# jbr_MDR1986VE3 register map
Registers are 32-bit, access not given, no defined reset value unless marked. A register's access mark holds for its fields unless they carry their own. Addresses are absolute; registers are grouped by the start of their names; [hi:lo] are bit positions; {n}, {i} and the like mark numbered series; 'fields as' and 'values as' point back to an identical list.

## SSP3
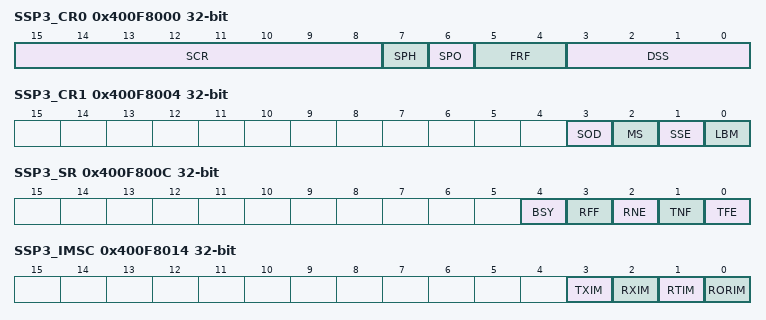
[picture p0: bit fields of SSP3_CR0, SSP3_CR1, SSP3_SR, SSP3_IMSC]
0x400F8000 SSP3_CR0
  [15:8] SCR, [7] SPH, [6] SPO, [5:4] FRF, [3:0] DSS
0x400F8004 SSP3_CR1
  [3] SOD, [2] MS, [1] SSE, [0] LBM
0x400F8008 SSP3_DR
  [15:0] DATA
0x400F800C SSP3_SR
  [4] BSY, [3] RFF, [2] RNE, [1] TNF, [0] TFE
0x400F8010 SSP3_CPSR
  [7:0] CPSDVSR
0x400F8014 SSP3_IMSC
  [3] TXIM, [2] RXIM, [1] RTIM, [0] RORIM
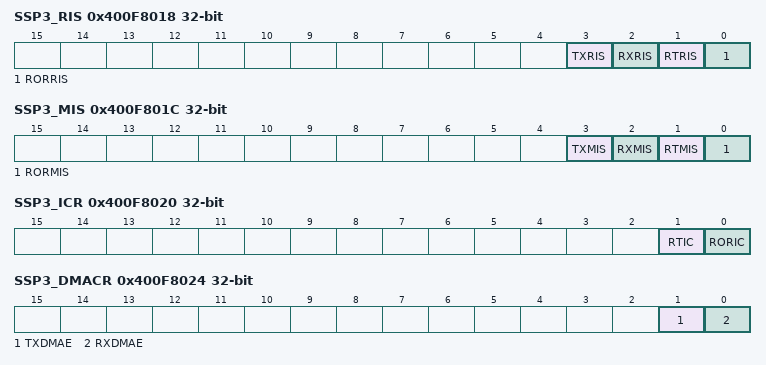
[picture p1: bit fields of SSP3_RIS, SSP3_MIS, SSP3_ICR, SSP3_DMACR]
0x400F8018 SSP3_RIS
  [3] TXRIS, [2] RXRIS, [1] RTRIS, [0] RORRIS
0x400F801C SSP3_MIS
  [3] TXMIS, [2] RXMIS, [1] RTMIS, [0] RORMIS
0x400F8020 SSP3_ICR
  [1] RTIC, [0] RORIC
0x400F8024 SSP3_DMACR
  [1] TXDMAE, [0] RXDMAE

## SSP4
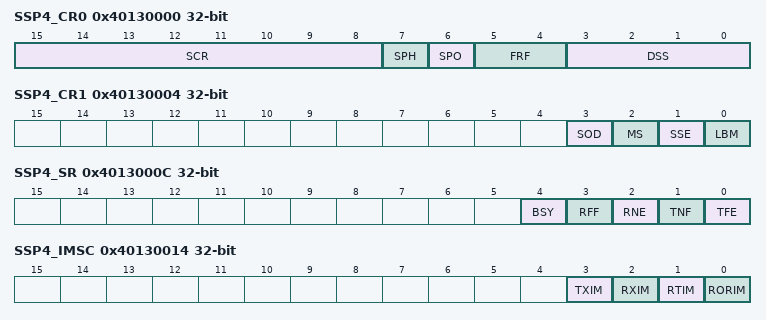
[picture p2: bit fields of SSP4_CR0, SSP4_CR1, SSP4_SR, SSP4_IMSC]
0x40130000 SSP4_CR0
  [15:8] SCR, [7] SPH, [6] SPO, [5:4] FRF, [3:0] DSS
0x40130004 SSP4_CR1
  [3] SOD, [2] MS, [1] SSE, [0] LBM
0x40130008 SSP4_DR
  [15:0] DATA
0x4013000C SSP4_SR
  [4] BSY, [3] RFF, [2] RNE, [1] TNF, [0] TFE
0x40130010 SSP4_CPSR
  [7:0] CPSDVSR
0x40130014 SSP4_IMSC
  [3] TXIM, [2] RXIM, [1] RTIM, [0] RORIM
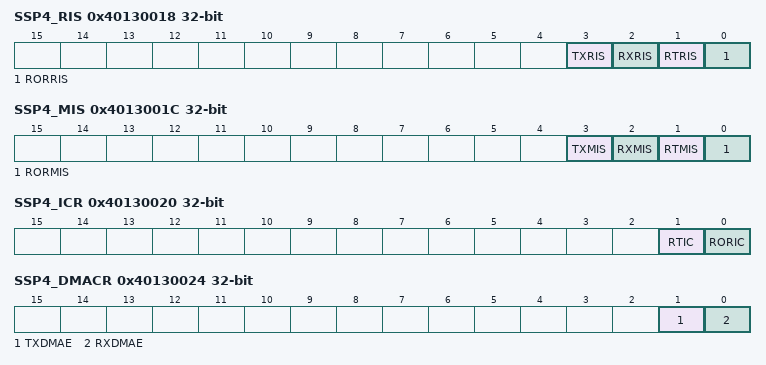
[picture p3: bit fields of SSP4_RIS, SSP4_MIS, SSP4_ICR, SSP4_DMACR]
0x40130018 SSP4_RIS
  [3] TXRIS, [2] RXRIS, [1] RTRIS, [0] RORRIS
0x4013001C SSP4_MIS
  [3] TXMIS, [2] RXMIS, [1] RTMIS, [0] RORMIS
0x40130020 SSP4_ICR
  [1] RTIC, [0] RORIC
0x40130024 SSP4_DMACR
  [1] TXDMAE, [0] RXDMAE

## MIL
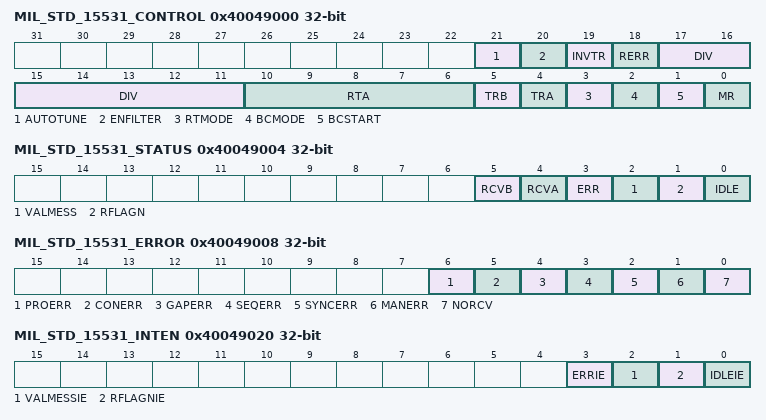
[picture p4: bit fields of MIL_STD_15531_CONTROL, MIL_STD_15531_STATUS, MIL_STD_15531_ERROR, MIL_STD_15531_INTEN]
0x40049000 MIL_STD_15531_CONTROL
  [21] AUTOTUNE, [20] ENFILTER, [19] INVTR, [18] RERR, [17:11] DIV, [10:6] RTA, [5] TRB, [4] TRA, [3] RTMODE, [2] BCMODE, [1] BCSTART, [0] MR
0x40049004 MIL_STD_15531_STATUS
  [5] RCVB, [4] RCVA, [3] ERR, [2] VALMESS, [1] RFLAGN, [0] IDLE
0x40049008 MIL_STD_15531_ERROR
  [6] PROERR, [5] CONERR, [4] GAPERR, [3] SEQERR, [2] SYNCERR, [1] MANERR, [0] NORCV
0x4004900C MIL_STD_15531_CommandWord1
0x40049010 MIL_STD_15531_CommandWord2
0x40049014 MIL_STD_15531_ModeData
0x40049018 MIL_STD_15531_StatusWord1
0x4004901C MIL_STD_15531_StatusWord2
0x40049020 MIL_STD_15531_INTEN
  [3] ERRIE, [2] VALMESSIE, [1] RFLAGNIE, [0] IDLEIE
0x40049024 MIL_STD_15531_MSG
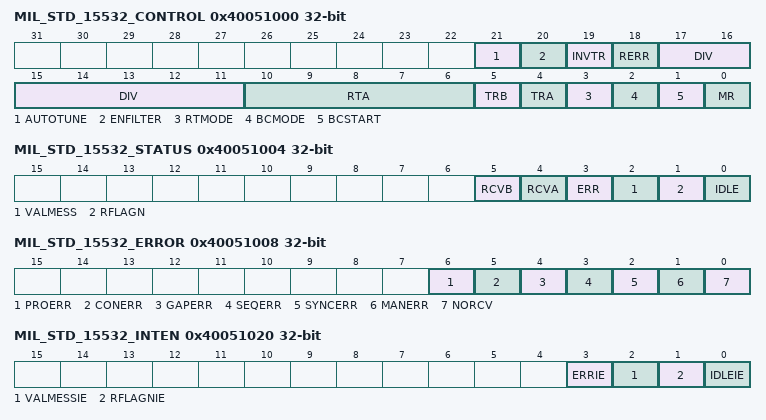
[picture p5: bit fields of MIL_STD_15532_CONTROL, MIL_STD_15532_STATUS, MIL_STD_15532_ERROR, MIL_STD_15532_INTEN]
0x40051000 MIL_STD_15532_CONTROL
  fields as MIL_STD_15531_CONTROL
0x40051004 MIL_STD_15532_STATUS
  [5] RCVB, [4] RCVA, [3] ERR, [2] VALMESS, [1] RFLAGN, [0] IDLE
0x40051008 MIL_STD_15532_ERROR
  fields as MIL_STD_15531_ERROR
0x4005100C MIL_STD_15532_CommandWord1
0x40051010 MIL_STD_15532_CommandWord2
0x40051014 MIL_STD_15532_ModeData
0x40051018 MIL_STD_15532_StatusWord1
0x4005101C MIL_STD_15532_StatusWord2
0x40051020 MIL_STD_15532_INTEN
  [3] ERRIE, [2] VALMESSIE, [1] RFLAGNIE, [0] IDLEIE
0x40051024 MIL_STD_15532_MSG

## ARINC429T
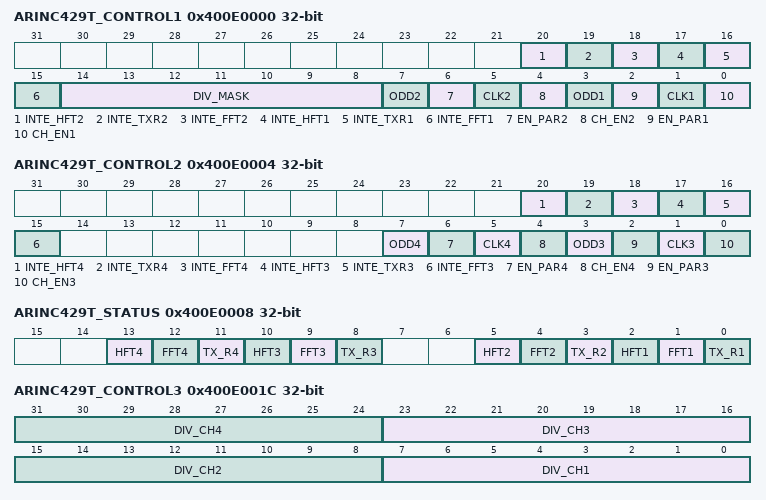
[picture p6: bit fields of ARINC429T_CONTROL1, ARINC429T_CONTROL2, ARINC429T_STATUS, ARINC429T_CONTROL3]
0x400E0000 ARINC429T_CONTROL1
  [20] INTE_HFT2, [19] INTE_TXR2, [18] INTE_FFT2, [17] INTE_HFT1, [16] INTE_TXR1, [15] INTE_FFT1, [14:8] DIV_MASK, [7] ODD2, [6] EN_PAR2, [5] CLK2, [4] CH_EN2, [3] ODD1, [2] EN_PAR1, [1] CLK1, [0] CH_EN1
0x400E0004 ARINC429T_CONTROL2
  [20] INTE_HFT4, [19] INTE_TXR4, [18] INTE_FFT4, [17] INTE_HFT3, [16] INTE_TXR3, [15] INTE_FFT3, [7] ODD4, [6] EN_PAR4, [5] CLK4, [4] CH_EN4, [3] ODD3, [2] EN_PAR3, [1] CLK3, [0] CH_EN3
0x400E0008 ARINC429T_STATUS
  [13] HFT4, [12] FFT4, [11] TX_R4, [10] HFT3, [9] FFT3, [8] TX_R3, [5] HFT2, [4] FFT2, [3] TX_R2, [2] HFT1, [1] FFT1, [0] TX_R1
{0x400E0008+4i} ARINC429T_DATA{i}_T (i=1..4)
0x400E001C ARINC429T_CONTROL3
  [8n-1:8n-8] DIV_CH{n} (n=1..4)

## ARINC429R
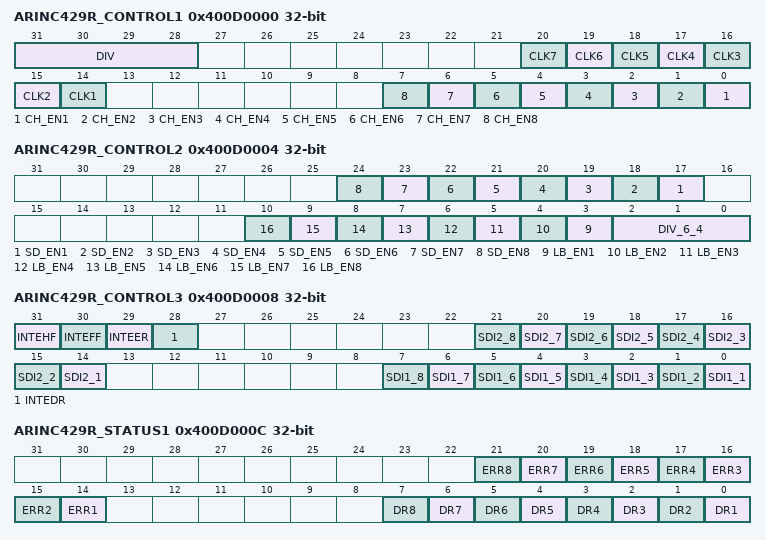
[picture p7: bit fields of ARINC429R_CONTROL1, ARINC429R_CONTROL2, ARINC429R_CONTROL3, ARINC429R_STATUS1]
0x400D0000 ARINC429R_CONTROL1
  [31:28] DIV, [n+13] CLK{n} (n=1..7), [n-1] CH_EN{n} (n=1..8)
0x400D0004 ARINC429R_CONTROL2
  [n+16] SD_EN{n} (n=1..8), [n+2] LB_EN{n} (n=1..8), [2:0] DIV_6_4
0x400D0008 ARINC429R_CONTROL3
  [31] INTEHF, [30] INTEFF, [29] INTEER, [28] INTEDR, [n+13] SDI2_{n} (n=1..8), [n-1] SDI1_{n} (n=1..8)
0x400D000C ARINC429R_STATUS1
  [n+13] ERR{n} (n=1..8), [n-1] DR{n} (n=1..8)
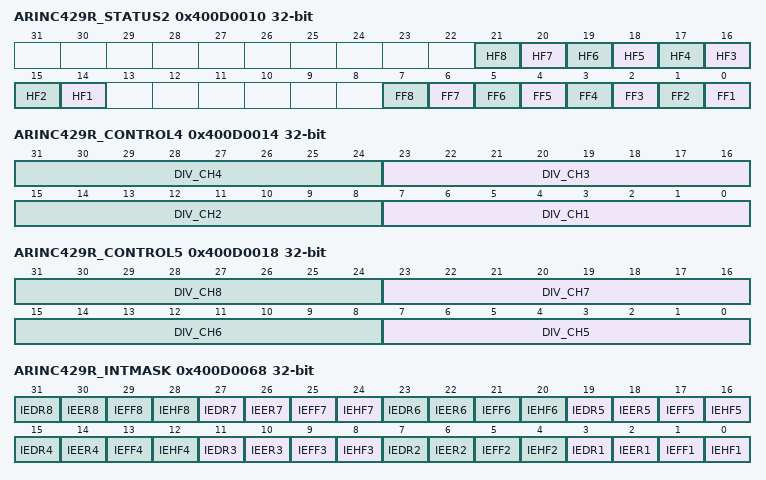
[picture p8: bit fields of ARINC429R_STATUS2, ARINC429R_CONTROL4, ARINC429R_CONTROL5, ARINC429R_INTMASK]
0x400D0010 ARINC429R_STATUS2
  [n+13] HF{n} (n=1..8), [n-1] FF{n} (n=1..8)
0x400D0014 ARINC429R_CONTROL4
  [8n-1:8n-8] DIV_CH{n} (n=1..4)
0x400D0018 ARINC429R_CONTROL5
  [8n-33:8n-40] DIV_CH{n} (n=5..8)
0x400D001C ARINC429R_CHANNEL
0x400D0020 ARINC429R_LABEL
0x400D0024 ARINC429R_DATA_R
0x400D0068 ARINC429R_INTMASK
  [4n-1] IEDR{n} (n=1..8), [4n-2] IEER{n} (n=1..8), [4n-3] IEFF{n} (n=1..8), [4n-4] IEHF{n} (n=1..8)
